# A31G12x register map
Vendor: VENDOR ABOV Semiconductor Co., Ltd.; Series: A31G12x; File version: 1.0
CPU: CM0+ r0p1, little endian, no MPU, no FPU, VTOR, 2 interrupt priority bits
Registers are 32-bit, read-write, reset 0x0 unless marked. A register's access mark holds for its fields unless they carry their own. Offsets are from the block's base; [hi:lo] are bit positions; {n}, {i} and the like mark numbered series; 'fields as' and 'values as' point back to an identical list.

## SCUCG — System Control Unit: Clock Generation
Base 0x40001800
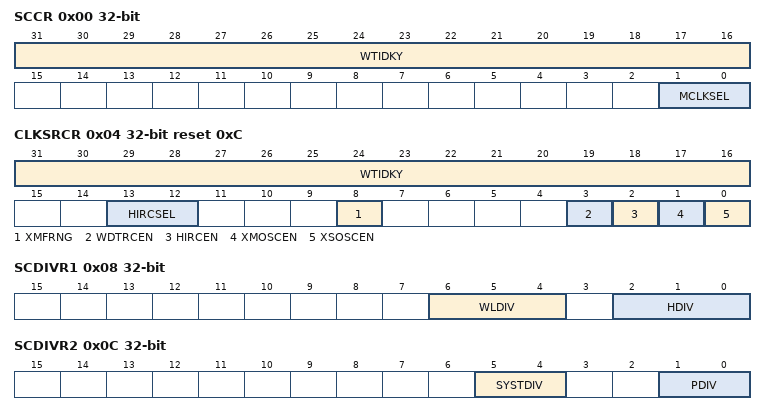
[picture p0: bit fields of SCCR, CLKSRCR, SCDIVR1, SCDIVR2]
0x00 SCCR — System Clock Control Register
  [31:16] WTIDKY wo — Write Identification Key (0x570a)
    0x570A=Value (Key Value (0x570a))
  [1:0] MCLKSEL — Main Clock Selection, MCLK
    0=HIRC (High Frequency Internal RC Oscillator (40MHz), HIRC); 1=XMOSC (External Main Oscillator (2 - 40MHz), XMOSC); 2=XSOSC (External Sub Oscillator (32.768kHz), XSOSC); 3=WDTRC (Internal Watch-Dog Timer RC Oscillator (40kHz), WDTRC)
0x04 CLKSRCR reset 0xC — Clock Source Control Register
  [31:16] WTIDKY wo — Write Identification Key (0xa507)
    0xA507=Value (Key Value (0xa507))
  [13:12] HIRCSEL — HIRC Frequency Selection
    0=HIRC1 (40MHz HIRC); 1=HIRC2 (20MHz HIRC); 2=HIRC4 (10MHz HIRC); 3=HIRC8 (5MHz HIRC)
  [8] XMFRNG — Main Oscillator Type and Frequency Range Selection
    0=X-tal for XMOSC, 2 to 16MHz; 1=Clock (External Clock for XMOSC, 2MHz to 40MHz)
  [3] WDTRCEN — WDTRC Enable
    0=Disable WDTRC; 1=Enable WDTRC
  [2] HIRCEN — HIRC Enable
    0=Disable HIRC; 1=Enable HIRC
  [1] XMOSCEN — XMOSC Enable
    0=Disable XMOSC; 1=Enable XMOSC
  [0] XSOSCEN — XSOSC Enable
    0=Disable XSOSC; 1=Enable XSOSC
0x08 SCDIVR1 — System Clock Divide Register 1
  [6:4] WLDIV — Clock Divide for Watch Timer and LCD Driver, Divider 2
    0=MCLK64; 1=MCLK128; 2=MCLK256; 3=MCLK512; 4=MCLK1024
  [2:0] HDIV — Clock Divide for HCLK, Divider 0
    0=MCLK16; 1=MCLK8; 2=MCLK4; 3=MCLK2; 4=MCLK1
0x0C SCDIVR2 — System Clock Divide Register 2
  [5:4] SYSTDIV — Clock Divide for SysTick Timer, Divider 3
    0=HCLK1; 1=HCLK2; 2=HCLK4; 3=HCLK8
  [1:0] PDIV — Clock Divide for PCLK, Divider 1
    0=HCLK1; 1=HCLK2; 2=HCLK4; 3=HCLK8
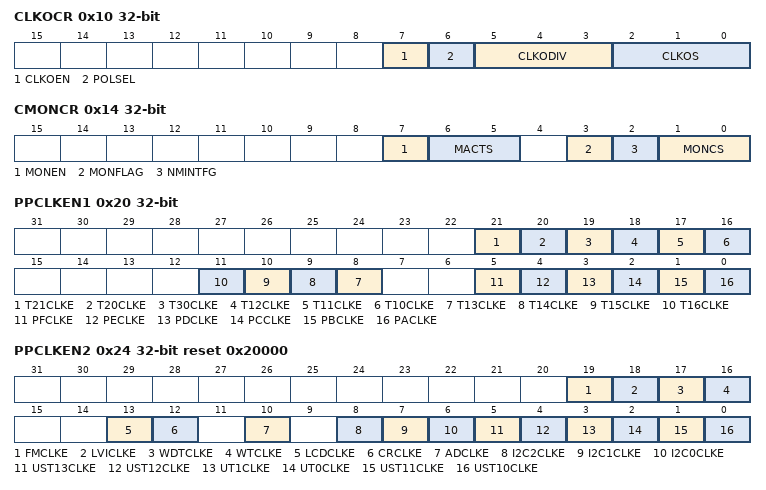
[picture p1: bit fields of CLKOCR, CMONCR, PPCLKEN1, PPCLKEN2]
0x10 CLKOCR — Clock Output Control Register
  [7] CLKOEN — Clock Output Enable
    0=Disable clock output; 1=Enable clock output
  [6] POLSEL — Clock Output Polarity Selection when Disable
    0=Low (Low level during disable); 1=High level during disable
  [5:3] CLKODIV — Output Clock Divide, Divider 4
    0=SelectedClock1; 1=SelectedClock2; 2=SelectedClock4; 3=SelectedClock8; 4=SelectedClock16; 5=SelectedClock32; 6=SelectedClock64; 7=SelectedClock128
  [2:0] CLKOS — Clock Output Selection
    0=MCLK (Select MCLK.); 1=WDTRC (Select WDTRC.); 2=HIRC (Select HIRC.); 3=HCLK (Select HCLK.); 4=PCLK (Select PCLK.)
0x14 CMONCR — Clock Monitoring Control Register
  [7] MONEN — Clock Monitoring Enable
    0=Disable clock monitoring; 1=Enable clock monitoring
  [6:5] MACTS — Clock Monitoring Action Selection
    0=FlagChk (No action by clock monitoring, but flags will be set/cleared on condition); 1=RstGen (Reset generation by clock monitoring); 2=SysClkChg (The system clock will be changed to the WDTRC regardless of MCLKSEL[1:0] bits of system clock control register (SCU_SCCR) only when the MCLK is selected for monitoring)
  [3] MONFLAG — Clock Monitoring Result Flag
    0=NotReady (The clock to be monitored is not ready); 1=Ready (The clock to be monitored is ready)
  [2] NMINTFG — Clock Monitoring Interrupt Flag
    0=No request occurred; 1=Request occurred
  [1:0] MONCS — Monitored Clock Selection
    0=MCLK (Select MCLK.); 1=HIRC (Select HIRC.); 2=XMOSC (Select XMOSC.); 3=XSOSC (Select XSOSC.)
0x20 PPCLKEN1 — Peripheral Clock Enable Register 1
  [all] fields
    0=Disable clock; 1=Enable clock
  [21] T21CLKE — TIMER21 Clock Enable
  [20] T20CLKE — TIMER20 Clock Enable
  [19] T30CLKE — TIMER30 Clock Enable
  [18] T12CLKE — TIMER12 Clock Enable
  [17] T11CLKE — TIMER11 Clock Enable
  [16] T10CLKE — TIMER10 Clock Enable
  [n-5] T{n}CLKE (n=13..16) — TIMER{n} Clock Enable
  [5] PFCLKE — Port F Clock Enable
  [4] PECLKE — Port E Clock Enable
  [3] PDCLKE — Port D Clock Enable
  [2] PCCLKE — Port C Clock Enable
  [1] PBCLKE — Port B Clock Enable
  [0] PACLKE — Port A Clock Enable
0x24 PPCLKEN2 reset 0x20000 — Peripheral Clock Enable Register 2
  [all] fields
    0=Disable clock; 1=Enable clock
  [19] FMCLKE — FMC (Flash Memory Controller) Clock Enable
  [18] LVICLKE — LVI (Low Voltage Indicator) Clock Enable
  [17] WDTCLKE — WDT (Watch-Dog Timer) Clock Enable
  [16] WTCLKE — WT (Watch Timer) Clock Enable
  [13] LCDCLKE — LCD (LCD Driver) Clock Enable
  [12] CRCLKE — CRC (Cyclic Redundancy Check) Clock Enable
  [10] ADCLKE — ADC (Analog to Digital Converter) Clock Enable
  [8] I2C2CLKE — I2C2 (Inter-IC) Clock Enable
  [7] I2C1CLKE — I2C1 (Inter-IC) Clock Enable
  [6] I2C0CLKE — I2C0 (Inter-IC) Clock Enable
  [5] UST13CLKE — USART13 Clock Enable
  [4] UST12CLKE — USART12 Clock Enable
  [3] UT1CLKE — UART1 Clock Enable
  [2] UT0CLKE — UART0 Clock Enable
  [1] UST11CLKE — USART11 Clock Enable
  [0] UST10CLKE — USART10 Clock Enable
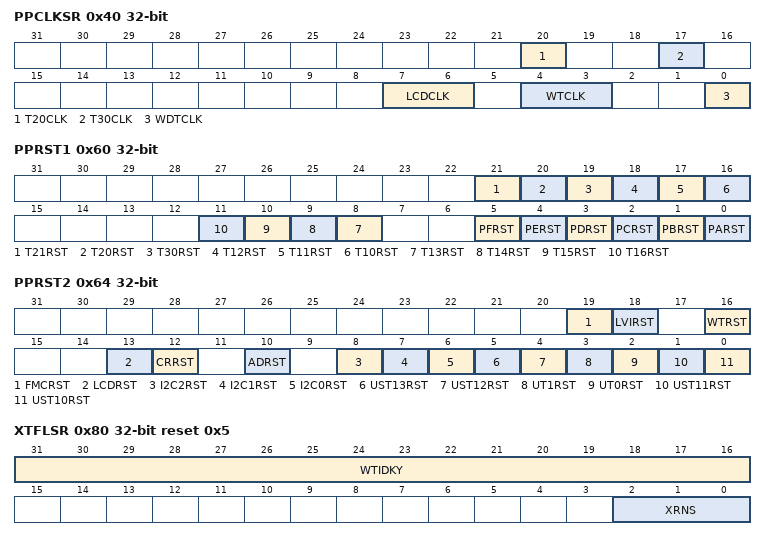
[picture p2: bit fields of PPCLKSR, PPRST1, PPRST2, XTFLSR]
0x40 PPCLKSR — Peripheral Clock Selection Register
  [20] T20CLK — TIMER20 Clock Selection
    0=XSOSC (XSOSC clock); 1=PCLK (PCLK clock)
  [17] T30CLK — TIMER30 Clock Selection
    0=MCLK (MCLK clock); 1=PCLK (PCLK clock)
  [7:6] LCDCLK — LCD (LCD Driver) Clock Selection
    0=DividedMCLK (A clock of the MCLK which is divided by divider 2); 1=XSOSC (XSOSC clock); 2=WDTRC (WDTRC clock)
  [4:3] WTCLK — WT (Watch Timer) Clock Selection
    values as LCDCLK
  [0] WDTCLK — WDT (Watch-Dog Timer) Clock Selection
    0=WDTRC (WDTRC clock); 1=PCLK (PCLK clock)
0x60 PPRST1 — Peripheral Reset Register 1
  [21] T21RST — TIMER21 Reset
  [20] T20RST — TIMER20 Reset
  [19] T30RST — TIMER30 Reset
  [18] T12RST — TIMER12 Reset
  [17] T11RST — TIMER11 Reset
  [16] T10RST — TIMER10 Reset
  [n-5] T{n}RST (n=13..16) — TIMER{n} Reset
  [5] PFRST — Port F Reset
  [4] PERST — Port E Reset
  [3] PDRST — Port D Reset
  [2] PCRST — Port C Reset
  [1] PBRST — Port B Reset
  [0] PARST — Port A Reset
0x64 PPRST2 — Peripheral Reset Register 2
  [19] FMCRST — FMC (Flash Memory Controller) Reset
  [18] LVIRST — LVI (Low Voltage Indicator) Reset
  [16] WTRST — WT (Watch Timer) Reset
  [13] LCDRST — LCD (LCD Driver) Reset
  [12] CRRST — CRC (Cyclic Redundancy Check) Reset
  [10] ADRST — ADC (Analog to Digital Converter) Reset
  [8] I2C2RST — I2C2 (Inter-IC) Reset
  [7] I2C1RST — I2C1 (Inter-IC) Reset
  [6] I2C0RST — I2C0 (Inter-IC) Reset
  [5] UST13RST — USART13 Reset
  [4] UST12RST — USART12 Reset
  [3] UT1RST — UART1 Reset
  [2] UT0RST — UART0 Reset
  [1] UST11RST — USART11 Reset
  [0] UST10RST — USART10 Reset
0x80 XTFLSR reset 0x5 — X-tal Filter Selection Register
  [31:16] WTIDKY wo — Write Identification Key (0x9b37)
    0x9B37=Value (Key Value (0x9b37))
  [2:0] XRNS — External Main Oscillator Filter Selection
    0=LE4p5MHz (x-tal LE 4.5MHz); 1=LE6p5MHz (4.5MHz GT x-tal LE 6.5MHz); 2=LE8p5MHz (6.5MHz GT x-tal LE 8.5MHz); 3=LE10p5MHz (8.5MHz GT x-tal LE 10.5MHz); 4=LE12p5MHz (10.5MHz GT x-tal LE 12.5MHz); 5=LE16p5MHz (12.5MHz GT x-tal LE 16.5MHz)

## Notices in the file
Copyright (C) 2012 ARM Limited. All rights reserved.
Purpose: System Viewer Description (SVD) Example (Schema Version 1.1)
This is a description of a none-existent and incomplete device
for demonstration purposes only.
Redistribution and use in source and binary forms, with or without
modification, are permitted provided that the following conditions are met:
- Redistributions of source code must retain the above copyright
notice, this list of conditions and the following disclaimer.
- Redistributions in binary form must reproduce the above copyright
notice, this list of conditions and the following disclaimer in the
documentation and/or other materials provided with the distribution.
- Neither the name of ARM nor the names of its contributors may be used
to endorse or promote products derived from this software without
specific prior written permission.
THIS SOFTWARE IS PROVIDED BY THE COPYRIGHT HOLDERS AND CONTRIBUTORS "AS IS"
AND ANY EXPRESS OR IMPLIED WARRANTIES, INCLUDING, BUT NOT LIMITED TO, THE
IMPLIED WARRANTIES OF MERCHANTABILITY AND FITNESS FOR A PARTICULAR PURPOSE
ARE DISCLAIMED. IN NO EVENT SHALL COPYRIGHT HOLDERS AND CONTRIBUTORS BE
LIABLE FOR ANY DIRECT, INDIRECT, INCIDENTAL, SPECIAL, EXEMPLARY, OR
CONSEQUENTIAL DAMAGES (INCLUDING, BUT NOT LIMITED TO, PROCUREMENT OF
SUBSTITUTE GOODS OR SERVICES; LOSS OF USE, DATA, OR PROFITS; OR BUSINESS
INTERRUPTION) HOWEVER CAUSED AND ON ANY THEORY OF LIABILITY, WHETHER IN
CONTRACT, STRICT LIABILITY, OR TORT (INCLUDING NEGLIGENCE OR OTHERWISE)
ARISING IN ANY WAY OUT OF THE USE OF THIS SOFTWARE, EVEN IF ADVISED OF THE
POSSIBILITY OF SUCH DAMAGE.
